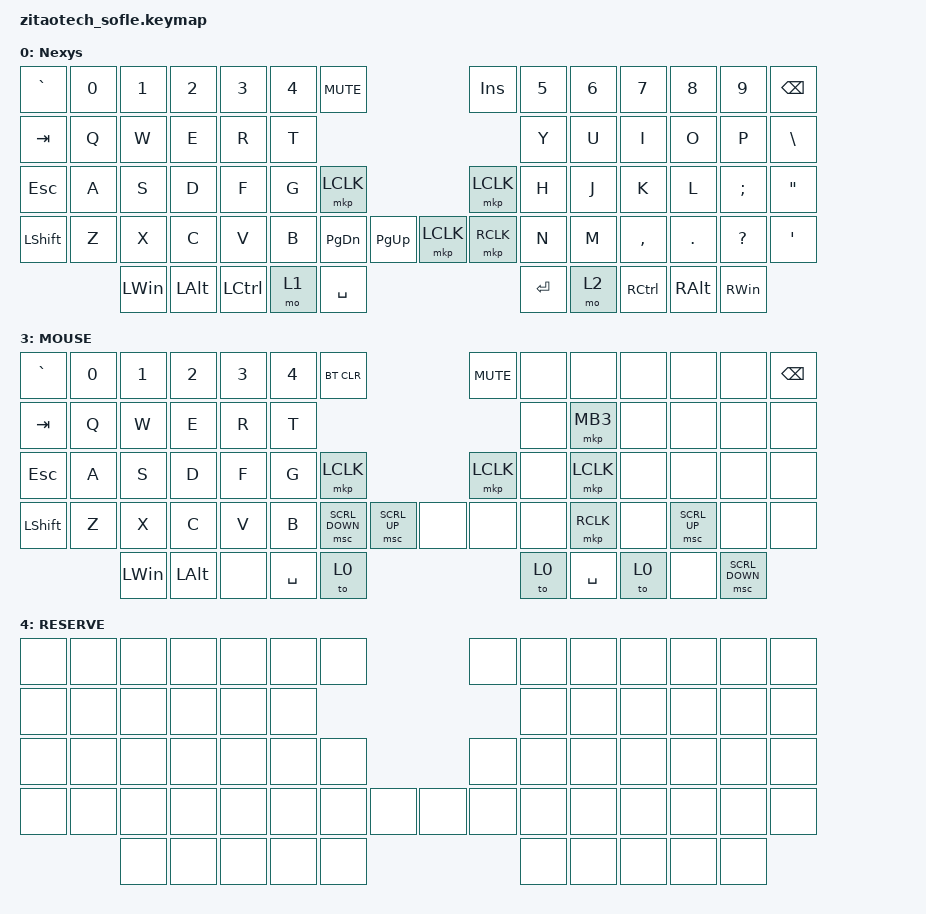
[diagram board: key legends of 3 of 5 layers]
/*
 * Copyright (c) 2025 ZitaoTech
 *
 * SPDX-License-Identifier: MIT
 */

#include <behaviors.dtsi>
#include <dt-bindings/zmk/keys.h>
#include <dt-bindings/zmk/bt.h>
#include <dt-bindings/zmk/outputs.h>
#include <dt-bindings/zmk/mouse.h>
#include <dt-bindings/zmk/backlight.h>
#include <dt-bindings/zmk/ext_power.h>
#include <dt-bindings/zmk/rgb.h>

#define FUNC 1
#define RES 2
#define BOT bootloader

/ {
    input_processors {

        zip_temp_layer: zip_temp_layer {
            compatible = "zmk,input-processor-temp-layer";
            #input-processor-cells = <2>;
        };

        ip_behaviors0: ip_behaviors0 {
            compatible = "zmk,input-processor-behaviors";
            #input-processor-cells = <0>;
            type = <INPUT_EV_KEY>;
            codes = <INPUT_BTN_0>;
            bindings = <&kp RIGHT>;
        };
        ip_behaviors1: ip_behaviors1 {
            compatible = "zmk,input-processor-behaviors";
            #input-processor-cells = <0>;
            type = <INPUT_EV_KEY>;
            codes = <INPUT_BTN_1>;
            bindings = <&kp LEFT>;
        };
        ip_behaviors2: ip_behaviors2 {
            compatible = "zmk,input-processor-behaviors";
            #input-processor-cells = <0>;
            type = <INPUT_EV_KEY>;
            codes = <INPUT_BTN_2>;
            bindings = <&kp DOWN>;
        };
        ip_behaviors3: ip_behaviors3 {
            compatible = "zmk,input-processor-behaviors";
            #input-processor-cells = <0>;
            type = <INPUT_EV_KEY>;
            codes = <INPUT_BTN_3>;
            bindings = <&kp UP>;
        };
    };
};

/ {
    behaviors {
        td0: tap_dance_0 {
            compatible = "zmk,behavior-tap-dance";
            #binding-cells = <0>;
            tapping-term-ms = <400>;
            bindings = <&mkp LCLK>, <&bt BT_CLR>;
        };
    };
    behaviors {
        hm: homerow_mods {
            compatible = "zmk,behavior-hold-tap";
            #binding-cells = <2>;
            tapping-term-ms = <500>;
            bindings = <&kp &kp>;
        };
    };

    behaviors {
         sp_sc: behavior_spacescroll {
           compatible = "zmk,behavior-hold-tap";
           #binding-cells = <2>;
           flavor = "tap-preferred";     /* 单击优先 */
           tapping-term-ms = <200>;       /* 长按阈值 */
           bindings = <&none &kp>;        /* hold=none, tap=space */
        };
    };

    behaviors {
        BLE_encoder: BLE_encoder {
            compatible = "zmk,behavior-sensor-rotate";
            #sensor-binding-cells = <0>;
            bindings = <&bt BT_NXT>, <&bt BT_PRV>;
        };
    };

    keymap {
        compatible = "zmk,keymap";

        /* ===========================================================
         * Layer 0: Nexys (默认层)
         * 风格继承自原自定义版，保留 GRAVE/INSERT/ESCAPE 等位置
         * =========================================================== */
        default_layer {
            display-name = "Nexys";
            bindings = <
&kp GRAVE   &kp N0    &kp N1    &kp N2   &kp N3   &kp N4    &kp C_MUTE                &kp INSERT                       &kp N5    &kp N6    &kp N7   &kp N8   &kp N9  &kp BSPC
&kp TAB     &kp Q     &kp W     &kp E    &kp R    &kp T                                                               &kp Y     &kp U     &kp I    &kp O    &kp P   &kp BACKSLASH
&kp ESCAPE  &kp A     &kp S     &kp D    &kp F    &kp G     &mkp LCLK                  &mkp LCLK                        &kp H     &kp J     &kp K    &kp L    &kp SEMI &kp DOUBLE_QUOTES
&kp LSHFT   &kp Z     &kp X     &kp C    &kp V    &kp B     &kp PG_DN  &kp PG_UP       &mkp LCLK    &mkp RCLK          &kp N     &kp M     &kp COMMA &kp DOT  &kp QUESTION  &kp SINGLE_QUOTE
                    &kp LEFT_WIN  &kp LALT  &kp LEFT_CONTROL  &mo 1   &kp SPACE  &kp ENTER                            &mo 2     &kp RIGHT_CONTROL  &kp RALT  &kp RIGHT_WIN
            >;
            sensor-bindings = <&inc_dec_kp C_VOL_UP C_VOL_DN &inc_dec_kp LEFT RIGHT>;
        };

        /* ===========================================================
         * Layer 1: Neural (功能层)
         * F-键 + 窗口管理/桌面切换快捷键 + 鼠标操作 + RGB/背光
         * =========================================================== */
        func_layer {
            display-name = "Neural";
            bindings = <
&kp F10       &kp F12     &kp F1          &kp F2       &kp F3           &kp F4          &bt BT_CLR    &kp C_MUTE    &kp F5        &kp F6      &kp F7          &kp F8           &kp F9        &kp F10
&trans          &mkp MCLK  &kp LC(LG(LEFT))  &kp LA(LS(TAB))  &kp LC(LS(TAB))  &kp LC(LS(T))  &trans  &kp HOME      &kp UP_ARROW  &kp END     &kp PAGE_UP     &kp DEL
&rgb_ug RGB_TOG &mkp RCLK  &kp LC(LG(RIGHT)) &kp LA(TAB)      &kp LC(TAB)      &trans         &mkp RCLK  &mkp RCLK  &trans        &kp LEFT    &kp DOWN_ARROW  &kp RIGHT_ARROW  &kp PAGE_DOWN  &trans
&out OUT_TOG    &mkp LCLK  &kp LS(DELETE)  &kp LC(INSERT)  &kp LS(INSERT)  &kp LC(W)     &kp LC(LS(LA(DOUBLE_QUOTES)))  &kp LC(LS(LA(PERCENT)))  &bl BL_DEC  &bl BL_INC  &trans  &trans  &trans  &trans  &trans  &trans
                    &trans  &trans          &trans          &trans          &trans          &trans      &trans          &trans      &trans
            >;
            sensor-bindings = <&inc_dec_kp C_VOL_UP C_VOL_DN &inc_dec_kp BACKSPACE DELETE>;
        };

        /* ===========================================================
         * Layer 2: Symbol (符号层)
         * 特殊字符 + 数字小键盘
         * =========================================================== */
        sym_layer {
            display-name = "Symbol";
            bindings = <
&kp B  &kp N0  &kp N1  &kp N2  &kp N3  &kp U  &none      &none     &kp PERCENT     &kp AT_SIGN      &kp LEFT_BRACKET      &kp RIGHT_BRACKET      &kp POUND      &kp TILDE
&kp X  &kp N4  &kp N5  &kp N6  &kp N7  &kp MINUS  &kp MINUS  &kp PLUS  &kp LEFT_BRACE  &kp RIGHT_BRACE  &kp CARET             &kp DOLLAR
&kp L  &kp N8  &kp N9  &kp A   &kp B   &kp DOT  &none      &none     &kp UNDERSCORE  &kp EQUAL        &kp LEFT_PARENTHESIS  &kp RIGHT_PARENTHESIS  &kp COLON      &kp AMPERSAND
&kp F  &kp C   &kp D   &kp E   &kp F   &kp COMMA  &none  &none  &none  &none  &kp SLASH  &kp ASTERISK  &kp LESS_THAN  &kp GREATER_THAN  &kp EXCLAMATION  &kp PIPE
                   &none  &none  &none  &none  &none  &none  &none  &none  &trans
            >;
            sensor-bindings = <&BLE_encoder &inc_dec_kp BACKSPACE DEL>;
        };

        /* ===========================================================
         * Layer 3: MOUSE (鼠标层)
         * 透过 to(0) 回到默认层, 保留上游设计
         * =========================================================== */
        MOUSE_layer {
            display-name = "MOUSE";
            bindings = <
&kp GRAVE  &kp N0   &kp N1    &kp N2   &kp N3    &kp N4    &bt BT_CLR                      &kp C_MUTE       &none    &none    &none   &none         &none  &kp BSPC
&kp TAB    &kp Q    &kp W     &kp E    &kp R     &kp T                                                             &none    &mkp MB3 &none   &none         &none  &none
&kp ESCAPE &kp A    &kp S     &kp D    &kp F     &kp G     &mkp LCLK                       &mkp LCLK        &none    &mkp LCLK &none   &none         &none  &none
&kp LSHFT  &kp Z    &kp X     &kp C    &kp V     &kp B     &msc SCRL_DOWN  &msc SCRL_UP   &none  &none     &none    &mkp RCLK &none   &msc SCRL_UP  &none  &none
                      &kp LEFT_WIN  &kp LALT  &none      &kp SPACE  &to 0                             &to 0  &kp SPACE  &to 0    &none   &msc SCRL_DOWN
            >;
        };

        /* ===========================================================
         * Layer 4: RESERVE (保留层, 全空)
         * =========================================================== */
        RES_layer {
            display-name = "RESERVE";
            bindings = <
&none  &none  &none  &none  &none  &none  &none                    &none            &none  &none  &none  &none  &none  &none
&none  &none  &none  &none  &none  &none                                                  &none  &none  &none  &none  &none  &none
&none  &none  &none  &none  &none  &none  &none                    &none            &none  &none  &none  &none  &none  &none
&none  &none  &none  &none  &none  &none  &none  &none            &none  &none     &none  &none  &none  &none  &none  &none
                      &none  &none  &none  &none  &none                                      &none  &none  &none  &none  &none
            >;
        };
    };
};
